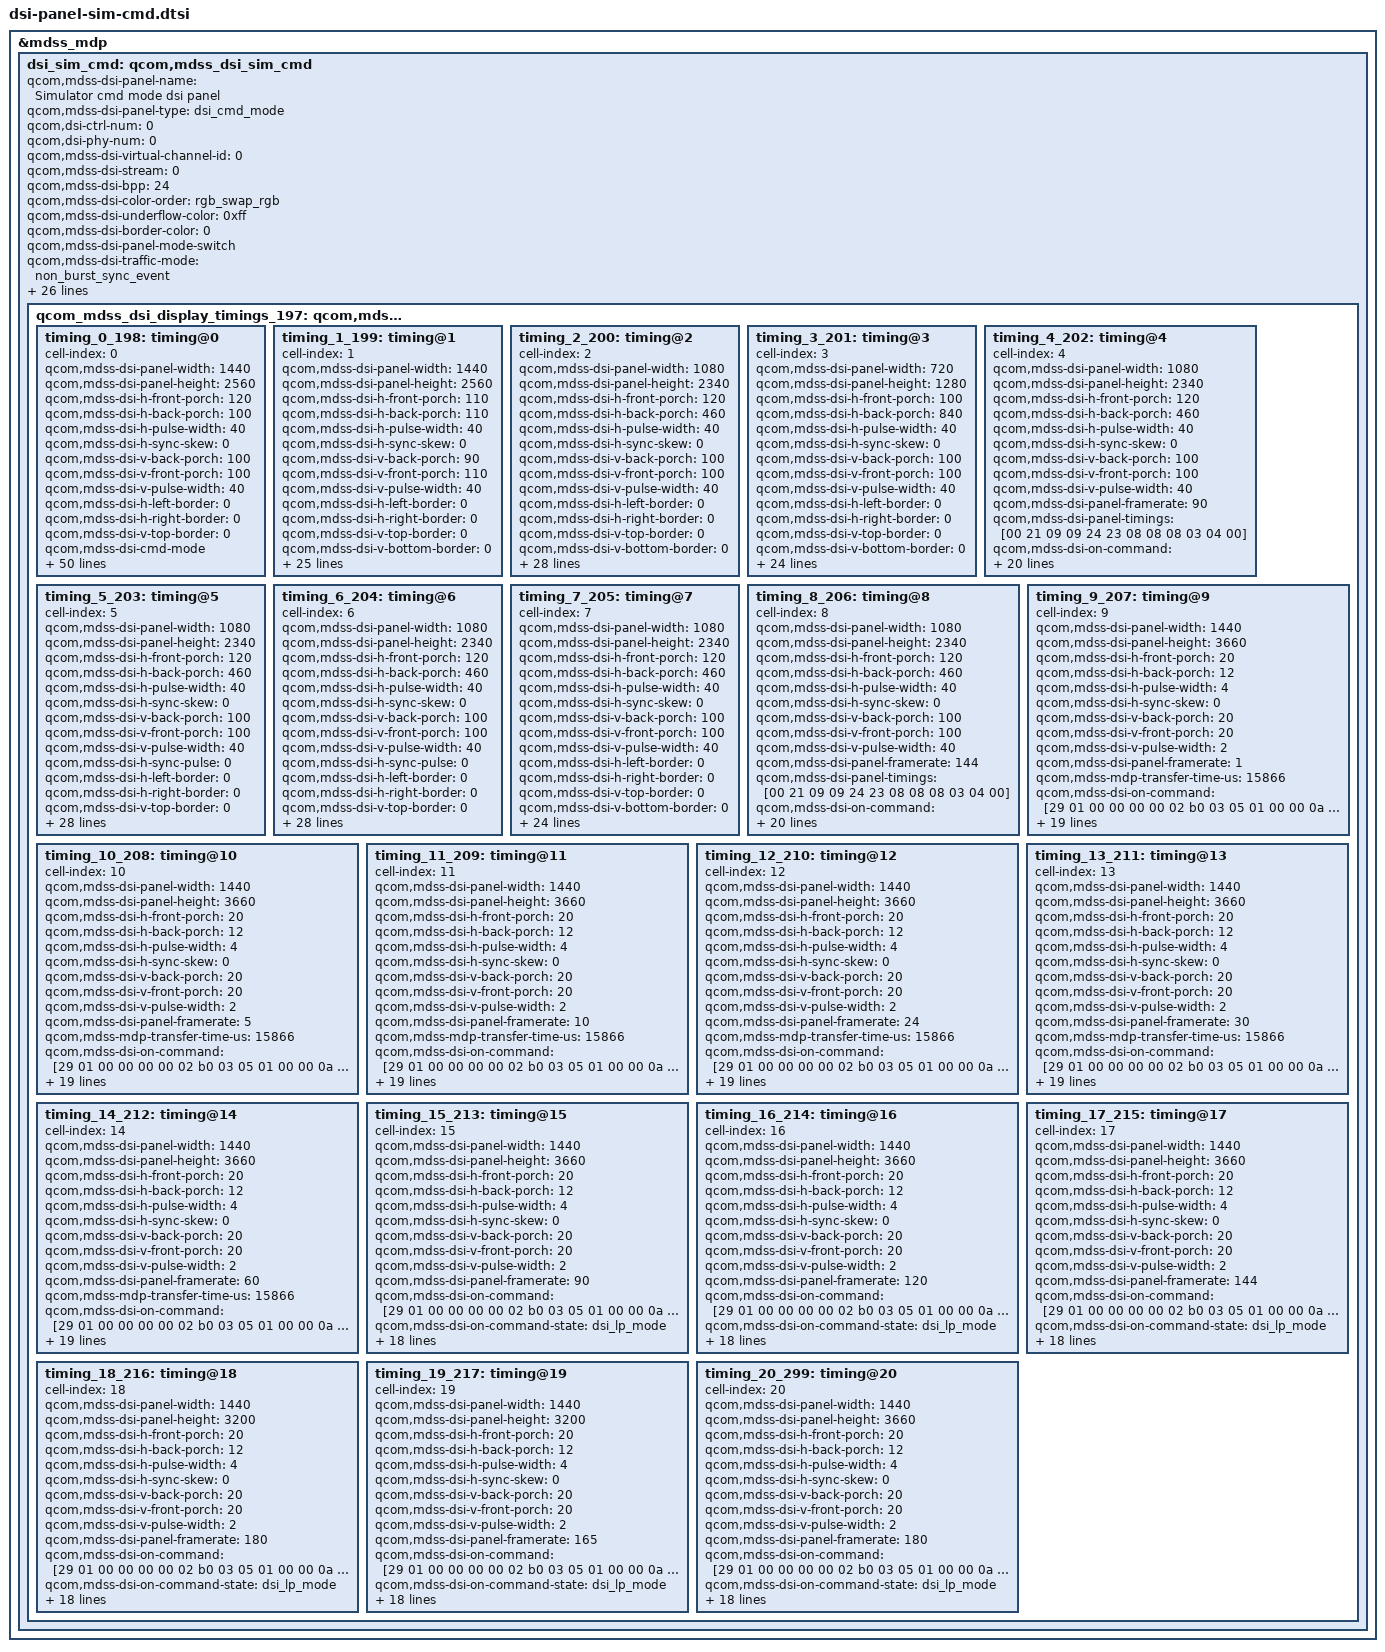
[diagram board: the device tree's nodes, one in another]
// SPDX-License-Identifier: BSD-3-Clause
/*
 * Copyright (c) Qualcomm Technologies, Inc. and/or its subsidiaries.
 */

&mdss_mdp {
	dsi_sim_cmd: qcom,mdss_dsi_sim_cmd {
		qcom,mdss-dsi-panel-name = "Simulator cmd mode dsi panel";
		qcom,mdss-dsi-panel-type = "dsi_cmd_mode";

		qcom,dsi-ctrl-num = <0>;
		qcom,dsi-phy-num = <0>;

		qcom,mdss-dsi-virtual-channel-id = <0>;
		qcom,mdss-dsi-stream = <0>;
		qcom,mdss-dsi-bpp = <24>;
		qcom,mdss-dsi-color-order = "rgb_swap_rgb";
		qcom,mdss-dsi-underflow-color = <0xff>;
		qcom,mdss-dsi-border-color = <0>;
		qcom,mdss-dsi-panel-mode-switch;
		qcom,mdss-dsi-traffic-mode = "non_burst_sync_event";
		qcom,mdss-dsi-bllp-eof-power-mode;
		qcom,mdss-dsi-bllp-power-mode;
		qcom,mdss-dsi-lane-0-state;
		qcom,mdss-dsi-lane-1-state;
		qcom,mdss-dsi-lane-2-state;
		qcom,mdss-dsi-lane-3-state;
		qcom,mdss-dsi-reset-sequence = <1 10>, <0 10>, <1 10>;
		qcom,mdss-dsi-t-clk-post = <0x03>;
		qcom,mdss-dsi-t-clk-pre = <0x27>;
		qcom,mdss-dsi-bl-max-level = <4095>;
		qcom,mdss-dsi-dma-trigger = "trigger_sw";
		qcom,mdss-dsi-mdp-trigger = "none";
		qcom,mdss-dsi-te-pin-select = <1>;
		qcom,mdss-dsi-wr-mem-start = <0x2c>;
		qcom,mdss-dsi-wr-mem-continue = <0x3c>;
		qcom,mdss-dsi-te-dcs-command = <1>;
		qcom,mdss-dsi-te-check-enable;
		qcom,mdss-dsi-te-using-wd;
		qcom,mdss-dsi-te-using-te-pin;
		qcom,mdss-dsi-panel-hdr-enabled;
		qcom,mdss-dsi-panel-hdr-color-primaries = <14500 15500 32000
			17000 15500 30000 8000 3000>;
		qcom,mdss-dsi-panel-peak-brightness = <4200000>;
		qcom,mdss-dsi-panel-blackness-level = <3230>;
		qcom,panel-ack-disabled;
		qcom,qsync-enable;

		qcom_mdss_dsi_display_timings_197: qcom,mdss-dsi-display-timings {
			timing_0_198: timing@0 {
				cell-index = <0>;
				qcom,mdss-dsi-panel-width = <1440>;
				qcom,mdss-dsi-panel-height = <2560>;
				qcom,mdss-dsi-h-front-porch = <120>;
				qcom,mdss-dsi-h-back-porch = <100>;
				qcom,mdss-dsi-h-pulse-width = <40>;
				qcom,mdss-dsi-h-sync-skew = <0>;
				qcom,mdss-dsi-v-back-porch = <100>;
				qcom,mdss-dsi-v-front-porch = <100>;
				qcom,mdss-dsi-v-pulse-width = <40>;
				qcom,mdss-dsi-h-left-border = <0>;
				qcom,mdss-dsi-h-right-border = <0>;
				qcom,mdss-dsi-v-top-border = <0>;
				qcom,mdss-dsi-cmd-mode;
				qcom,mdss-dsi-video-mode;
				qcom,mdss-dsi-v-bottom-border = <0>;
				qcom,mdss-dsi-panel-framerate = <60>;
				qcom,dsi-wd-jitter-enable;
				qcom,mdss-dsi-panel-jitter = <0x2 0x1>;
				qcom,dsi-wd-ltj-max-jitter = <0x4 0x1>;
				qcom,dsi-wd-ltj-time-sec = <3600>;
				qcom,mdss-dsi-panel-timings =
					[00 21 09 09 24 23 08 08 08 03 04 00];
				qcom,cmd-on-commands =
					[29 01 00 00 00 00 02 b0 03
					05 01 00 00 0a 00 01 00
					/* Soft reset, wait 10ms */
					15 01 00 00 0a 00 02 3a 77
					/* Set Pixel format (24 bpp) */
					39 01 00 00 0a 00 05 2a 00 00 04 ff
					/* Set Column address */
					39 01 00 00 0a 00 05 2b 00 00 05 9f
					/* Set page address */
					15 01 00 00 0a 00 02 35 00
					/* Set tear on */
					39 01 00 00 0a 00 03 44 00 00
					/* Set tear scan line */
					15 01 00 00 0a 00 02 51 ff
					/* write display brightness */
					15 01 00 00 0a 00 02 53 24
					/* write control brightness */
					15 01 00 00 0a 00 02 55 00
					/* CABC brightness */
					05 01 00 00 78 00 01 11
					/* exit sleep mode, wait 120ms */
					05 01 00 00 10 00 01 29];
				qcom,vid-on-commands =
					[29 01 00 00 00 00 02 b0 03
					05 01 00 00 0a 00 01 00
					/* Soft reset, wait 10ms */
					15 01 00 00 0a 00 02 3a 77
					/* Set Pixel format (24 bpp) */
					39 01 00 00 0a 00 05 2a 00 00 04 ff
					/* Set Column address */
					39 01 00 00 0a 00 05 2b 00 00 05 9f
					/* Set page address */
					15 01 00 00 0a 00 02 35 00
					/* Set tear on */
					39 01 00 00 0a 00 03 44 00 00
					/* Set tear scan line */
					15 01 00 00 0a 00 02 51 ff
					/* write display brightness */
					15 01 00 00 0a 00 02 53 24
					/* write control brightness */
					15 01 00 00 0a 00 02 55 00
					/* CABC brightness */
					05 01 00 00 f0 00 01 00];
				qcom,mdss-dsi-on-command = [
					15 01 00 00 00 00 02 FE 00
					29 01 00 00 00 00 05 2A 00 0A 01 CF
					29 01 00 00 00 00 05 2B 00 00 01 C5
					29 01 00 00 00 00 05 30 00 00 01 C5
					29 01 00 00 00 00 05 31 00 0A 01 CF
					15 01 00 00 00 00 02 35 00
					15 01 00 00 00 00 02 53 20
					15 01 00 00 00 00 02 51 FF
					15 01 00 00 00 00 02 63 FF
					05 01 00 00 00 00 02 12 00
					05 01 00 00 32 00 02 11 00
					05 01 00 00 00 00 02 29 00
				];
				qcom,mdss-dsi-on-command-state = "dsi_lp_mode";
				qcom,mdss-dsi-off-command =
					[05 01 00 00 32 00 02 28 00
					05 01 00 00 78 00 02 10 00];
				qcom,mdss-dsi-off-command-state = "dsi_hs_mode";
				qcom,video-mode-switch-out-commands = [
				  39 01 00 00 00 00 03 b0 a5 00
				  07 01 00 00 00 00 02 01 00
				  39 01 00 00 00 00 06 b2 00 5d 04 80 49
				];
				qcom,video-mode-switch-out-commands-state = "dsi_lp_mode";
				qcom,video-mode-switch-in-commands = [
				  39 01 00 00 00 00 03 b0 a5 00
				  07 01 00 00 00 00 02 01 00
				  39 01 00 00 00 00 06 b2 00 5d 04 80 49
				  15 01 00 00 00 00 02 3d 10
				  15 01 00 00 00 00 02 36 00
				  15 01 00 00 00 00 02 55 0c
				];
				qcom,video-mode-switch-in-commands-state = "dsi_lp_mode";
				qcom,cmd-mode-switch-in-commands = [
				  39 01 00 00 00 00 03 b0 a5 00
				  07 01 00 00 00 00 02 01 00
				  39 01 00 00 00 00 06 b2 00 5d 04 80 49
				  15 01 00 00 00 00 02 3d 11
				  15 01 00 00 00 00 02 36 00
				  15 01 00 00 00 00 02 55 0b
				];
				qcom,cmd-mode-switch-in-commands-state = "dsi_lp_mode";
				qcom,cmd-mode-switch-out-commands = [
				  39 01 00 00 00 00 03 b0 a5 00
				  07 01 00 00 00 00 02 01 00
				  39 01 00 00 00 00 06 b2 00 5d 01 02 49
				];
				qcom,cmd-mode-switch-out-commands-state = "dsi_lp_mode";
				qcom,mdss-dsi-qsync-on-commands =
					[15 01 00 00 00 00 02 51 00];
				qcom,mdss-dsi-qsync-on-commands-state =
					"dsi_hs_mode";
				qcom,mdss-dsi-qsync-off-commands =
					[15 01 00 00 00 00 02 51 00];
				qcom,mdss-dsi-qsync-off-commands-state =
					"dsi_hs_mode";

				qcom,compression-mode = "dsc";
				qcom,mdss-dsc-slice-height = <40>;
				qcom,mdss-dsc-slice-width = <720>;
				qcom,mdss-dsc-slice-per-pkt = <1>;
				qcom,mdss-dsc-bit-per-component = <8>;
				qcom,mdss-dsc-bit-per-pixel = <8>;
				qcom,mdss-dsc-block-prediction-enable;
			};

			timing_1_199: timing@1 {
				cell-index = <1>;
				qcom,mdss-dsi-panel-width = <1440>;
				qcom,mdss-dsi-panel-height = <2560>;
				qcom,mdss-dsi-h-front-porch = <110>;
				qcom,mdss-dsi-h-back-porch = <110>;
				qcom,mdss-dsi-h-pulse-width = <40>;
				qcom,mdss-dsi-h-sync-skew = <0>;
				qcom,mdss-dsi-v-back-porch = <90>;
				qcom,mdss-dsi-v-front-porch = <110>;
				qcom,mdss-dsi-v-pulse-width = <40>;
				qcom,mdss-dsi-h-left-border = <0>;
				qcom,mdss-dsi-h-right-border = <0>;
				qcom,mdss-dsi-v-top-border = <0>;
				qcom,mdss-dsi-v-bottom-border = <0>;
				qcom,mdss-dsi-panel-framerate = <60>;
				qcom,mdss-dsi-video-mode;
				qcom,mdss-dsi-panel-timings =
					[00 21 09 09 24 23 08 08 08 03 04 00];
				qcom,mdss-dsi-on-command =
					[29 01 00 00 00 00 02 b0 03
					05 01 00 00 0a 00 01 00
					/* Soft reset, wait 10ms */
					15 01 00 00 0a 00 02 3a 77
					/* Set Pixel format (24 bpp) */
					39 01 00 00 0a 00 05 2a 00 00 04 ff
					/* Set Column address */
					39 01 00 00 0a 00 05 2b 00 00 05 9f
					/* Set page address */
					15 01 00 00 0a 00 02 35 00
					/* Set tear on */
					39 01 00 00 0a 00 03 44 00 00
					/* Set tear scan line */
					15 01 00 00 0a 00 02 51 ff
					/* write display brightness */
					15 01 00 00 0a 00 02 53 24
					/* write control brightness */
					15 01 00 00 0a 00 02 55 00
					/* CABC brightness */
					05 01 00 00 f0 00 01 00];
				qcom,mdss-dsi-on-command-state = "dsi_lp_mode";
				qcom,mdss-dsi-off-command =
					[05 01 00 00 32 00 02 28 00
					05 01 00 00 78 00 02 10 00];
				qcom,mdss-dsi-off-command-state = "dsi_hs_mode";
				qcom,mdss-dsi-qsync-on-commands =
					[15 01 00 00 00 00 02 51 00];
				qcom,mdss-dsi-qsync-on-commands-state =
					"dsi_hs_mode";
				qcom,mdss-dsi-qsync-off-commands =
					[15 01 00 00 00 00 02 51 00];
				qcom,mdss-dsi-qsync-off-commands-state =
					"dsi_hs_mode";

				qcom,compression-mode = "dsc";
				qcom,mdss-dsc-slice-height = <40>;
				qcom,mdss-dsc-slice-width = <720>;
				qcom,mdss-dsc-slice-per-pkt = <1>;
				qcom,mdss-dsc-bit-per-component = <8>;
				qcom,mdss-dsc-bit-per-pixel = <8>;
				qcom,mdss-dsc-block-prediction-enable;
			};

			timing_2_200: timing@2 {
				cell-index = <2>;
				qcom,mdss-dsi-panel-width = <1080>;
				qcom,mdss-dsi-panel-height = <2340>;
				qcom,mdss-dsi-h-front-porch = <120>;
				qcom,mdss-dsi-h-back-porch = <460>;
				qcom,mdss-dsi-h-pulse-width = <40>;
				qcom,mdss-dsi-h-sync-skew = <0>;
				qcom,mdss-dsi-v-back-porch = <100>;
				qcom,mdss-dsi-v-front-porch = <100>;
				qcom,mdss-dsi-v-pulse-width = <40>;
				qcom,mdss-dsi-h-left-border = <0>;
				qcom,mdss-dsi-h-right-border = <0>;
				qcom,mdss-dsi-v-top-border = <0>;
				qcom,mdss-dsi-v-bottom-border = <0>;
				qcom,mdss-dsi-panel-framerate = <60>;
				qcom,dsi-wd-jitter-enable;
				qcom,mdss-dsi-panel-jitter = <0x2 0x1>;
				qcom,dsi-wd-ltj-max-jitter = <0x4 0x1>;
				qcom,dsi-wd-ltj-time-sec = <3600>;
				qcom,mdss-dsi-panel-timings =
					[00 21 09 09 24 23 08 08 08 03 04 00];
				qcom,mdss-dsi-on-command =
					[29 01 00 00 00 00 02 b0 03
					05 01 00 00 0a 00 01 00
					/* Soft reset, wait 10ms */
					15 01 00 00 0a 00 02 3a 77
					/* Set Pixel format (24 bpp) */
					39 01 00 00 0a 00 05 2a 00 00 04 ff
					/* Set Column address */
					39 01 00 00 0a 00 05 2b 00 00 05 9f
					/* Set page address */
					15 01 00 00 0a 00 02 35 00
					/* Set tear on */
					39 01 00 00 0a 00 03 44 00 00
					/* Set tear scan line */
					15 01 00 00 0a 00 02 51 ff
					/* write display brightness */
					15 01 00 00 0a 00 02 53 24
					 /* write control brightness */
					15 01 00 00 0a 00 02 55 00
					/* CABC brightness */
					05 01 00 00 f0 00 01 00];
				qcom,mdss-dsi-on-command-state = "dsi_lp_mode";
				qcom,mdss-dsi-off-command =
					[05 01 00 00 32 00 02 28 00
					05 01 00 00 78 00 02 10 00];
				qcom,mdss-dsi-off-command-state = "dsi_hs_mode";
				qcom,mdss-dsi-qsync-on-commands =
					[15 01 00 00 00 00 02 51 00];
				qcom,mdss-dsi-qsync-on-commands-state =
					"dsi_hs_mode";
				qcom,mdss-dsi-qsync-off-commands =
					[15 01 00 00 00 00 02 51 00];
				qcom,mdss-dsi-qsync-off-commands-state =
					"dsi_hs_mode";

				qcom,compression-mode = "dsc";
				qcom,mdss-dsc-slice-height = <20>;
				qcom,mdss-dsc-slice-width = <540>;
				qcom,mdss-dsc-slice-per-pkt = <1>;
				qcom,mdss-dsc-bit-per-component = <8>;
				qcom,mdss-dsc-bit-per-pixel = <8>;
				qcom,mdss-dsc-block-prediction-enable;
			};

			timing_3_201: timing@3 {
				cell-index = <3>;
				qcom,mdss-dsi-panel-width = <720>;
				qcom,mdss-dsi-panel-height = <1280>;
				qcom,mdss-dsi-h-front-porch = <100>;
				qcom,mdss-dsi-h-back-porch = <840>;
				qcom,mdss-dsi-h-pulse-width = <40>;
				qcom,mdss-dsi-h-sync-skew = <0>;
				qcom,mdss-dsi-v-back-porch = <100>;
				qcom,mdss-dsi-v-front-porch = <100>;
				qcom,mdss-dsi-v-pulse-width = <40>;
				qcom,mdss-dsi-h-left-border = <0>;
				qcom,mdss-dsi-h-right-border = <0>;
				qcom,mdss-dsi-v-top-border = <0>;
				qcom,mdss-dsi-v-bottom-border = <0>;
				qcom,mdss-dsi-panel-framerate = <60>;
				qcom,mdss-dsi-panel-timings =
					[00 21 09 09 24 23 08 08 08 03 04 00];
				qcom,mdss-dsi-on-command =
					[29 01 00 00 00 00 02 b0 03
					05 01 00 00 0a 00 01 00
					/* Soft reset, wait 10ms */
					15 01 00 00 0a 00 02 3a 77
					/* Set Pixel format (24 bpp) */
					39 01 00 00 0a 00 05 2a 00 00 04 ff
					/* Set Column address */
					39 01 00 00 0a 00 05 2b 00 00 05 9f
					/* Set page address */
					15 01 00 00 0a 00 02 35 00
					/* Set tear on */
					39 01 00 00 0a 00 03 44 00 00
					/* Set tear scan line */
					15 01 00 00 0a 00 02 51 ff
					/* write display brightness */
					15 01 00 00 0a 00 02 53 24
					 /* write control brightness */
					15 01 00 00 0a 00 02 55 00
					/* CABC brightness */
					05 01 00 00 f0 00 01 00];
				qcom,mdss-dsi-on-command-state = "dsi_lp_mode";
				qcom,mdss-dsi-off-command =
					[05 01 00 00 32 00 02 28 00
					05 01 00 00 78 00 02 10 00];
				qcom,mdss-dsi-off-command-state = "dsi_hs_mode";
				qcom,mdss-dsi-qsync-on-commands =
					[15 01 00 00 00 00 02 51 00];
				qcom,mdss-dsi-qsync-on-commands-state =
					"dsi_hs_mode";
				qcom,mdss-dsi-qsync-off-commands =
					[15 01 00 00 00 00 02 51 00];
				qcom,mdss-dsi-qsync-off-commands-state =
					"dsi_hs_mode";

				qcom,compression-mode = "dsc";
				qcom,mdss-dsc-slice-height = <40>;
				qcom,mdss-dsc-slice-width = <360>;
				qcom,mdss-dsc-slice-per-pkt = <1>;
				qcom,mdss-dsc-bit-per-component = <8>;
				qcom,mdss-dsc-bit-per-pixel = <8>;
				qcom,mdss-dsc-block-prediction-enable;
			};

			timing_4_202: timing@4 {
				cell-index = <4>;
				qcom,mdss-dsi-panel-width = <1080>;
				qcom,mdss-dsi-panel-height = <2340>;
				qcom,mdss-dsi-h-front-porch = <120>;
				qcom,mdss-dsi-h-back-porch = <460>;
				qcom,mdss-dsi-h-pulse-width = <40>;
				qcom,mdss-dsi-h-sync-skew = <0>;
				qcom,mdss-dsi-v-back-porch = <100>;
				qcom,mdss-dsi-v-front-porch = <100>;
				qcom,mdss-dsi-v-pulse-width = <40>;
				qcom,mdss-dsi-panel-framerate = <90>;
				qcom,mdss-dsi-panel-timings =
					[00 21 09 09 24 23 08 08 08 03 04 00];
				qcom,mdss-dsi-on-command =
					[29 01 00 00 00 00 02 b0 03
					05 01 00 00 0a 00 01 00
					/* Soft reset, wait 10ms */
					15 01 00 00 0a 00 02 3a 77
					/* Set Pixel format (24 bpp) */
					39 01 00 00 0a 00 05 2a 00 00 04 ff
					/* Set Column address */
					39 01 00 00 0a 00 05 2b 00 00 05 9f
					/* Set page address */
					15 01 00 00 0a 00 02 35 00
					/* Set tear on */
					39 01 00 00 0a 00 03 44 00 00
					/* Set tear scan line */
					15 01 00 00 0a 00 02 51 ff
					/* write display brightness */
					15 01 00 00 0a 00 02 53 24
					 /* write control brightness */
					15 01 00 00 0a 00 02 55 00
					/* CABC brightness */
					05 01 00 00 78 00 01 11
					/* exit sleep mode, wait 120ms */
					05 01 00 00 10 00 01 29];
					/* Set display on, wait 16ms */
				qcom,mdss-dsi-on-command-state = "dsi_lp_mode";
				qcom,mdss-dsi-off-command =
					[05 01 00 00 32 00 02 28 00
					05 01 00 00 78 00 02 10 00];
				qcom,mdss-dsi-off-command-state = "dsi_hs_mode";
				qcom,mdss-dsi-qsync-on-commands =
					[15 01 00 00 00 00 02 51 00];
				qcom,mdss-dsi-qsync-on-commands-state =
					"dsi_hs_mode";
				qcom,mdss-dsi-qsync-off-commands =
					[15 01 00 00 00 00 02 51 00];
				qcom,mdss-dsi-qsync-off-commands-state =
					"dsi_hs_mode";

				qcom,compression-mode = "dsc";
				qcom,mdss-dsc-slice-height = <20>;
				qcom,mdss-dsc-slice-width = <540>;
				qcom,mdss-dsc-slice-per-pkt = <1>;
				qcom,mdss-dsc-bit-per-component = <8>;
				qcom,mdss-dsc-bit-per-pixel = <8>;
				qcom,mdss-dsc-block-prediction-enable;
			};

			timing_5_203: timing@5 {
				cell-index = <5>;
				qcom,mdss-dsi-panel-width = <1080>;
				qcom,mdss-dsi-panel-height = <2340>;
				qcom,mdss-dsi-h-front-porch = <120>;
				qcom,mdss-dsi-h-back-porch = <460>;
				qcom,mdss-dsi-h-pulse-width = <40>;
				qcom,mdss-dsi-h-sync-skew = <0>;
				qcom,mdss-dsi-v-back-porch = <100>;
				qcom,mdss-dsi-v-front-porch = <100>;
				qcom,mdss-dsi-v-pulse-width = <40>;
				qcom,mdss-dsi-h-sync-pulse = <0>;
				qcom,mdss-dsi-h-left-border = <0>;
				qcom,mdss-dsi-h-right-border = <0>;
				qcom,mdss-dsi-v-top-border = <0>;
				qcom,mdss-dsi-v-bottom-border = <0>;
				qcom,mdss-dsi-panel-framerate = <180>;
				qcom,dsi-wd-jitter-enable;
				qcom,mdss-dsi-panel-jitter = <0x2 0x1>;
				qcom,dsi-wd-ltj-max-jitter = <0x4 0x1>;
				qcom,dsi-wd-ltj-time-sec = <3600>;
				qcom,disable-rsc-solver;

				qcom,mdss-dsi-on-command =
					[29 01 00 00 00 00 02 b0 03
					05 01 00 00 0a 00 01 00
					/* Soft reset, wait 10ms */
					15 01 00 00 0a 00 02 3a 77
					/* Set Pixel format (24 bpp) */
					39 01 00 00 0a 00 05 2a 00 00 04 ff
					/* Set Column address */
					39 01 00 00 0a 00 05 2b 00 00 05 9f
					/* Set page address */
					15 01 00 00 0a 00 02 35 00
					/* Set tear on */
					39 01 00 00 0a 00 03 44 00 00
					/* Set tear scan line */
					15 01 00 00 0a 00 02 51 ff
					/* write display brightness */
					15 01 00 00 0a 00 02 53 24
					 /* write control brightness */
					15 01 00 00 0a 00 02 55 00];
					/* CABC brightness */

				qcom,mdss-dsi-on-command-state = "dsi_lp_mode";
				qcom,mdss-dsi-off-command =
					[05 01 00 00 32 00 02 28 00
					05 01 00 00 78 00 02 10 00];
				qcom,mdss-dsi-off-command-state = "dsi_hs_mode";
				qcom,mdss-dsi-qsync-on-commands =
					[15 01 00 00 00 00 02 51 00];
				qcom,mdss-dsi-qsync-on-commands-state =
					"dsi_hs_mode";
				qcom,mdss-dsi-qsync-off-commands =
					[15 01 00 00 00 00 02 51 00];
				qcom,mdss-dsi-qsync-off-commands-state =
					"dsi_hs_mode";

				qcom,compression-mode = "dsc";
				qcom,mdss-dsc-slice-height = <20>;
				qcom,mdss-dsc-slice-width = <540>;
				qcom,mdss-dsc-slice-per-pkt = <1>;
				qcom,mdss-dsc-bit-per-component = <8>;
				qcom,mdss-dsc-bit-per-pixel = <8>;
				qcom,mdss-dsc-block-prediction-enable;
			};

			timing_6_204: timing@6 {
				cell-index = <6>;
				qcom,mdss-dsi-panel-width = <1080>;
				qcom,mdss-dsi-panel-height = <2340>;
				qcom,mdss-dsi-h-front-porch = <120>;
				qcom,mdss-dsi-h-back-porch = <460>;
				qcom,mdss-dsi-h-pulse-width = <40>;
				qcom,mdss-dsi-h-sync-skew = <0>;
				qcom,mdss-dsi-v-back-porch = <100>;
				qcom,mdss-dsi-v-front-porch = <100>;
				qcom,mdss-dsi-v-pulse-width = <40>;
				qcom,mdss-dsi-h-sync-pulse = <0>;
				qcom,mdss-dsi-h-left-border = <0>;
				qcom,mdss-dsi-h-right-border = <0>;
				qcom,mdss-dsi-v-top-border = <0>;
				qcom,mdss-dsi-v-bottom-border = <0>;
				qcom,mdss-dsi-panel-framerate = <240>;
				qcom,dsi-wd-jitter-enable;
				qcom,mdss-dsi-panel-jitter = <0x2 0x1>;
				qcom,dsi-wd-ltj-max-jitter = <0x4 0x1>;
				qcom,dsi-wd-ltj-time-sec = <3600>;
				qcom,disable-rsc-solver;

				qcom,mdss-dsi-on-command =
					[29 01 00 00 00 00 02 b0 03
					05 01 00 00 0a 00 01 00
					/* Soft reset, wait 10ms */
					15 01 00 00 0a 00 02 3a 77
					/* Set Pixel format (24 bpp) */
					39 01 00 00 0a 00 05 2a 00 00 04 ff
					/* Set Column address */
					39 01 00 00 0a 00 05 2b 00 00 05 9f
					/* Set page address */
					15 01 00 00 0a 00 02 35 00
					/* Set tear on */
					39 01 00 00 0a 00 03 44 00 00
					/* Set tear scan line */
					15 01 00 00 0a 00 02 51 ff
					/* write display brightness */
					15 01 00 00 0a 00 02 53 24
					 /* write control brightness */
					15 01 00 00 0a 00 02 55 00
					/* CABC brightness */
					05 01 00 00 f0 00 01 00];
				qcom,mdss-dsi-on-command-state = "dsi_lp_mode";
				qcom,mdss-dsi-off-command =
					[05 01 00 00 32 00 02 28 00
					05 01 00 00 78 00 02 10 00];
				qcom,mdss-dsi-off-command-state = "dsi_hs_mode";
				qcom,mdss-dsi-qsync-on-commands =
					[15 01 00 00 00 00 02 51 00];
				qcom,mdss-dsi-qsync-on-commands-state =
					"dsi_hs_mode";
				qcom,mdss-dsi-qsync-off-commands =
					[15 01 00 00 00 00 02 51 00];
				qcom,mdss-dsi-qsync-off-commands-state =
					"dsi_hs_mode";

				qcom,compression-mode = "dsc";
				qcom,mdss-dsc-slice-height = <20>;
				qcom,mdss-dsc-slice-width = <540>;
				qcom,mdss-dsc-slice-per-pkt = <1>;
				qcom,mdss-dsc-bit-per-component = <8>;
				qcom,mdss-dsc-bit-per-pixel = <8>;
				qcom,mdss-dsc-block-prediction-enable;
			};

			timing_7_205: timing@7 {
				cell-index = <7>;
				qcom,mdss-dsi-panel-width = <1080>;
				qcom,mdss-dsi-panel-height = <2340>;
				qcom,mdss-dsi-h-front-porch = <120>;
				qcom,mdss-dsi-h-back-porch = <460>;
				qcom,mdss-dsi-h-pulse-width = <40>;
				qcom,mdss-dsi-h-sync-skew = <0>;
				qcom,mdss-dsi-v-back-porch = <100>;
				qcom,mdss-dsi-v-front-porch = <100>;
				qcom,mdss-dsi-v-pulse-width = <40>;
				qcom,mdss-dsi-h-left-border = <0>;
				qcom,mdss-dsi-h-right-border = <0>;
				qcom,mdss-dsi-v-top-border = <0>;
				qcom,mdss-dsi-v-bottom-border = <0>;
				qcom,mdss-dsi-panel-framerate = <120>;
				qcom,mdss-dsi-panel-timings =
					[00 21 09 09 24 23 08 08 08 03 04 00];
				qcom,mdss-dsi-on-command =
					[29 01 00 00 00 00 02 b0 03
					05 01 00 00 0a 00 01 00
					/* Soft reset, wait 10ms */
					15 01 00 00 0a 00 02 3a 77
					/* Set Pixel format (24 bpp) */
					39 01 00 00 0a 00 05 2a 00 00 04 ff
					/* Set Column address */
					39 01 00 00 0a 00 05 2b 00 00 05 9f
					/* Set page address */
					15 01 00 00 0a 00 02 35 00
					/* Set tear on */
					39 01 00 00 0a 00 03 44 00 00
					/* Set tear scan line */
					15 01 00 00 0a 00 02 51 ff
					/* write display brightness */
					15 01 00 00 0a 00 02 53 24
					 /* write control brightness */
					15 01 00 00 0a 00 02 55 00
					/* CABC brightness */
					05 01 00 00 78 00 01 11
					/* exit sleep mode, wait 120ms */
					05 01 00 00 10 00 01 29];
					/* Set display on, wait 16ms */
				qcom,mdss-dsi-on-command-state = "dsi_lp_mode";
				qcom,mdss-dsi-off-command =
					[05 01 00 00 32 00 02 28 00
					05 01 00 00 78 00 02 10 00];
				qcom,mdss-dsi-off-command-state = "dsi_hs_mode";
				qcom,mdss-dsi-qsync-on-commands =
					[15 01 00 00 00 00 02 51 00];
				qcom,mdss-dsi-qsync-on-commands-state =
					"dsi_hs_mode";
				qcom,mdss-dsi-qsync-off-commands =
					[15 01 00 00 00 00 02 51 00];
				qcom,mdss-dsi-qsync-off-commands-state =
					"dsi_hs_mode";

				qcom,compression-mode = "dsc";
				qcom,mdss-dsc-slice-height = <20>;
				qcom,mdss-dsc-slice-width = <540>;
				qcom,mdss-dsc-slice-per-pkt = <1>;
				qcom,mdss-dsc-bit-per-component = <8>;
				qcom,mdss-dsc-bit-per-pixel = <8>;
				qcom,mdss-dsc-block-prediction-enable;
			};

			timing_8_206: timing@8 {
				cell-index = <8>;
				qcom,mdss-dsi-panel-width = <1080>;
				qcom,mdss-dsi-panel-height = <2340>;
				qcom,mdss-dsi-h-front-porch = <120>;
				qcom,mdss-dsi-h-back-porch = <460>;
				qcom,mdss-dsi-h-pulse-width = <40>;
				qcom,mdss-dsi-h-sync-skew = <0>;
				qcom,mdss-dsi-v-back-porch = <100>;
				qcom,mdss-dsi-v-front-porch = <100>;
				qcom,mdss-dsi-v-pulse-width = <40>;
				qcom,mdss-dsi-panel-framerate = <144>;
				qcom,mdss-dsi-panel-timings =
					[00 21 09 09 24 23 08 08 08 03 04 00];
				qcom,mdss-dsi-on-command =
					[29 01 00 00 00 00 02 b0 03
					05 01 00 00 0a 00 01 00
					/* Soft reset, wait 10ms */
					15 01 00 00 0a 00 02 3a 77
					/* Set Pixel format (24 bpp) */
					39 01 00 00 0a 00 05 2a 00 00 04 ff
					/* Set Column address */
					39 01 00 00 0a 00 05 2b 00 00 05 9f
					/* Set page address */
					15 01 00 00 0a 00 02 35 00
					/* Set tear on */
					39 01 00 00 0a 00 03 44 00 00
					/* Set tear scan line */
					15 01 00 00 0a 00 02 51 ff
					/* write display brightness */
					15 01 00 00 0a 00 02 53 24
					 /* write control brightness */
					15 01 00 00 0a 00 02 55 00
					/* CABC brightness */
					05 01 00 00 78 00 01 11
					/* exit sleep mode, wait 120ms */
					05 01 00 00 10 00 01 29];
					/* Set display on, wait 16ms */
				qcom,mdss-dsi-on-command-state = "dsi_lp_mode";
				qcom,mdss-dsi-off-command =
					[05 01 00 00 32 00 02 28 00
					05 01 00 00 78 00 02 10 00];
				qcom,mdss-dsi-off-command-state = "dsi_hs_mode";
				qcom,mdss-dsi-qsync-on-commands =
					[15 01 00 00 00 00 02 51 00];
				qcom,mdss-dsi-qsync-on-commands-state =
					"dsi_hs_mode";
				qcom,mdss-dsi-qsync-off-commands =
					[15 01 00 00 00 00 02 51 00];
				qcom,mdss-dsi-qsync-off-commands-state =
					"dsi_hs_mode";

				qcom,compression-mode = "dsc";
				qcom,mdss-dsc-slice-height = <20>;
				qcom,mdss-dsc-slice-width = <540>;
				qcom,mdss-dsc-slice-per-pkt = <1>;
				qcom,mdss-dsc-bit-per-component = <8>;
				qcom,mdss-dsc-bit-per-pixel = <8>;
				qcom,mdss-dsc-block-prediction-enable;
			};

			timing_9_207: timing@9 {
				cell-index = <9>;
				qcom,mdss-dsi-panel-width = <1440>;
				qcom,mdss-dsi-panel-height = <3660>;
				qcom,mdss-dsi-h-front-porch = <20>;
				qcom,mdss-dsi-h-back-porch = <12>;
				qcom,mdss-dsi-h-pulse-width = <4>;
				qcom,mdss-dsi-h-sync-skew = <0>;
				qcom,mdss-dsi-v-back-porch = <20>;
				qcom,mdss-dsi-v-front-porch = <20>;
				qcom,mdss-dsi-v-pulse-width = <2>;
				qcom,mdss-dsi-panel-framerate = <1>;
				qcom,mdss-mdp-transfer-time-us = <15866>;
				qcom,mdss-dsi-on-command =
					[29 01 00 00 00 00 02 b0 03
					05 01 00 00 0a 00 01 00
					/* Soft reset, wait 10ms */
					15 01 00 00 0a 00 02 3a 77
					/* Set Pixel format (24 bpp) */
					39 01 00 00 0a 00 05 2a 00 00 04 ff
					/* Set Column address */
					39 01 00 00 0a 00 05 2b 00 00 05 9f
					/* Set page address */
					15 01 00 00 0a 00 02 35 00
					/* Set tear on */
					39 01 00 00 0a 00 03 44 00 00
					/* Set tear scan line */
					15 01 00 00 0a 00 02 51 ff
					/* write display brightness */
					15 01 00 00 0a 00 02 53 24
					 /* write control brightness */
					15 01 00 00 0a 00 02 55 00
					/* CABC brightness */
					05 01 00 00 78 00 01 11
					/* exit sleep mode, wait 120ms */
					05 01 00 00 10 00 01 29];
					/* Set display on, wait 16ms */
				qcom,mdss-dsi-on-command-state = "dsi_lp_mode";
				qcom,mdss-dsi-off-command =
					[05 01 00 00 32 00 02 28 00
					05 01 00 00 78 00 02 10 00];
				qcom,mdss-dsi-off-command-state = "dsi_hs_mode";
				qcom,mdss-dsi-qsync-on-commands =
					[15 01 00 00 00 00 02 51 00];
				qcom,mdss-dsi-qsync-on-commands-state =
					"dsi_hs_mode";
				qcom,mdss-dsi-qsync-off-commands =
					[15 01 00 00 00 00 02 51 00];
				qcom,mdss-dsi-qsync-off-commands-state =
					"dsi_hs_mode";

				qcom,compression-mode = "dsc";
				qcom,mdss-dsc-slice-height = <20>;
				qcom,mdss-dsc-slice-width = <720>;
				qcom,mdss-dsc-slice-per-pkt = <1>;
				qcom,mdss-dsc-bit-per-component = <8>;
				qcom,mdss-dsc-bit-per-pixel = <8>;
				qcom,mdss-dsc-block-prediction-enable;
			};

			timing_10_208: timing@10 {
				cell-index = <10>;
				qcom,mdss-dsi-panel-width = <1440>;
				qcom,mdss-dsi-panel-height = <3660>;
				qcom,mdss-dsi-h-front-porch = <20>;
				qcom,mdss-dsi-h-back-porch = <12>;
				qcom,mdss-dsi-h-pulse-width = <4>;
				qcom,mdss-dsi-h-sync-skew = <0>;
				qcom,mdss-dsi-v-back-porch = <20>;
				qcom,mdss-dsi-v-front-porch = <20>;
				qcom,mdss-dsi-v-pulse-width = <2>;
				qcom,mdss-dsi-panel-framerate = <5>;
				qcom,mdss-mdp-transfer-time-us = <15866>;
				qcom,mdss-dsi-on-command =
					[29 01 00 00 00 00 02 b0 03
					05 01 00 00 0a 00 01 00
					/* Soft reset, wait 10ms */
					15 01 00 00 0a 00 02 3a 77
					/* Set Pixel format (24 bpp) */
					39 01 00 00 0a 00 05 2a 00 00 04 ff
					/* Set Column address */
					39 01 00 00 0a 00 05 2b 00 00 05 9f
					/* Set page address */
					15 01 00 00 0a 00 02 35 00
					/* Set tear on */
					39 01 00 00 0a 00 03 44 00 00
					/* Set tear scan line */
					15 01 00 00 0a 00 02 51 ff
					/* write display brightness */
					15 01 00 00 0a 00 02 53 24
					 /* write control brightness */
					15 01 00 00 0a 00 02 55 00
					/* CABC brightness */
					05 01 00 00 78 00 01 11
					/* exit sleep mode, wait 120ms */
					05 01 00 00 10 00 01 29];
					/* Set display on, wait 16ms */
				qcom,mdss-dsi-on-command-state = "dsi_lp_mode";
				qcom,mdss-dsi-off-command =
					[05 01 00 00 32 00 02 28 00
					05 01 00 00 78 00 02 10 00];
				qcom,mdss-dsi-off-command-state = "dsi_hs_mode";
				qcom,mdss-dsi-qsync-on-commands =
					[15 01 00 00 00 00 02 51 00];
				qcom,mdss-dsi-qsync-on-commands-state =
					"dsi_hs_mode";
				qcom,mdss-dsi-qsync-off-commands =
					[15 01 00 00 00 00 02 51 00];
				qcom,mdss-dsi-qsync-off-commands-state =
					"dsi_hs_mode";

				qcom,compression-mode = "dsc";
				qcom,mdss-dsc-slice-height = <20>;
				qcom,mdss-dsc-slice-width = <720>;
				qcom,mdss-dsc-slice-per-pkt = <1>;
				qcom,mdss-dsc-bit-per-component = <8>;
				qcom,mdss-dsc-bit-per-pixel = <8>;
				qcom,mdss-dsc-block-prediction-enable;
			};

			timing_11_209: timing@11 {
				cell-index = <11>;
				qcom,mdss-dsi-panel-width = <1440>;
				qcom,mdss-dsi-panel-height = <3660>;
				qcom,mdss-dsi-h-front-porch = <20>;
				qcom,mdss-dsi-h-back-porch = <12>;
				qcom,mdss-dsi-h-pulse-width = <4>;
				qcom,mdss-dsi-h-sync-skew = <0>;
				qcom,mdss-dsi-v-back-porch = <20>;
				qcom,mdss-dsi-v-front-porch = <20>;
				qcom,mdss-dsi-v-pulse-width = <2>;
				qcom,mdss-dsi-panel-framerate = <10>;
				qcom,mdss-mdp-transfer-time-us = <15866>;
				qcom,mdss-dsi-on-command =
					[29 01 00 00 00 00 02 b0 03
					05 01 00 00 0a 00 01 00
					/* Soft reset, wait 10ms */
					15 01 00 00 0a 00 02 3a 77
					/* Set Pixel format (24 bpp) */
					39 01 00 00 0a 00 05 2a 00 00 04 ff
					/* Set Column address */
					39 01 00 00 0a 00 05 2b 00 00 05 9f
					/* Set page address */
					15 01 00 00 0a 00 02 35 00
					/* Set tear on */
					39 01 00 00 0a 00 03 44 00 00
					/* Set tear scan line */
					15 01 00 00 0a 00 02 51 ff
					/* write display brightness */
					15 01 00 00 0a 00 02 53 24
					 /* write control brightness */
					15 01 00 00 0a 00 02 55 00
					/* CABC brightness */
					05 01 00 00 78 00 01 11
					/* exit sleep mode, wait 120ms */
					05 01 00 00 10 00 01 29];
					/* Set display on, wait 16ms */
				qcom,mdss-dsi-on-command-state = "dsi_lp_mode";
				qcom,mdss-dsi-off-command =
					[05 01 00 00 32 00 02 28 00
					05 01 00 00 78 00 02 10 00];
				qcom,mdss-dsi-off-command-state = "dsi_hs_mode";
				qcom,mdss-dsi-qsync-on-commands =
					[15 01 00 00 00 00 02 51 00];
				qcom,mdss-dsi-qsync-on-commands-state =
					"dsi_hs_mode";
				qcom,mdss-dsi-qsync-off-commands =
					[15 01 00 00 00 00 02 51 00];
				qcom,mdss-dsi-qsync-off-commands-state =
					"dsi_hs_mode";

				qcom,compression-mode = "dsc";
				qcom,mdss-dsc-slice-height = <20>;
				qcom,mdss-dsc-slice-width = <720>;
				qcom,mdss-dsc-slice-per-pkt = <1>;
				qcom,mdss-dsc-bit-per-component = <8>;
				qcom,mdss-dsc-bit-per-pixel = <8>;
				qcom,mdss-dsc-block-prediction-enable;
			};

			timing_12_210: timing@12 {
				cell-index = <12>;
				qcom,mdss-dsi-panel-width = <1440>;
				qcom,mdss-dsi-panel-height = <3660>;
				qcom,mdss-dsi-h-front-porch = <20>;
				qcom,mdss-dsi-h-back-porch = <12>;
				qcom,mdss-dsi-h-pulse-width = <4>;
				qcom,mdss-dsi-h-sync-skew = <0>;
				qcom,mdss-dsi-v-back-porch = <20>;
				qcom,mdss-dsi-v-front-porch = <20>;
				qcom,mdss-dsi-v-pulse-width = <2>;
				qcom,mdss-dsi-panel-framerate = <24>;
				qcom,mdss-mdp-transfer-time-us = <15866>;
				qcom,mdss-dsi-on-command =
					[29 01 00 00 00 00 02 b0 03
					05 01 00 00 0a 00 01 00
					/* Soft reset, wait 10ms */
					15 01 00 00 0a 00 02 3a 77
					/* Set Pixel format (24 bpp) */
					39 01 00 00 0a 00 05 2a 00 00 04 ff
					/* Set Column address */
					39 01 00 00 0a 00 05 2b 00 00 05 9f
					/* Set page address */
					15 01 00 00 0a 00 02 35 00
					/* Set tear on */
					39 01 00 00 0a 00 03 44 00 00
					/* Set tear scan line */
					15 01 00 00 0a 00 02 51 ff
					/* write display brightness */
					15 01 00 00 0a 00 02 53 24
					 /* write control brightness */
					15 01 00 00 0a 00 02 55 00
					/* CABC brightness */
					05 01 00 00 78 00 01 11
					/* exit sleep mode, wait 120ms */
					05 01 00 00 10 00 01 29];
					/* Set display on, wait 16ms */
				qcom,mdss-dsi-on-command-state = "dsi_lp_mode";
				qcom,mdss-dsi-off-command =
					[05 01 00 00 32 00 02 28 00
					05 01 00 00 78 00 02 10 00];
				qcom,mdss-dsi-off-command-state = "dsi_hs_mode";
				qcom,mdss-dsi-qsync-on-commands =
					[15 01 00 00 00 00 02 51 00];
				qcom,mdss-dsi-qsync-on-commands-state =
					"dsi_hs_mode";
				qcom,mdss-dsi-qsync-off-commands =
					[15 01 00 00 00 00 02 51 00];
				qcom,mdss-dsi-qsync-off-commands-state =
					"dsi_hs_mode";

				qcom,compression-mode = "dsc";
				qcom,mdss-dsc-slice-height = <20>;
				qcom,mdss-dsc-slice-width = <720>;
				qcom,mdss-dsc-slice-per-pkt = <1>;
				qcom,mdss-dsc-bit-per-component = <8>;
				qcom,mdss-dsc-bit-per-pixel = <8>;
				qcom,mdss-dsc-block-prediction-enable;
			};

			timing_13_211: timing@13 {
				cell-index = <13>;
				qcom,mdss-dsi-panel-width = <1440>;
				qcom,mdss-dsi-panel-height = <3660>;
				qcom,mdss-dsi-h-front-porch = <20>;
				qcom,mdss-dsi-h-back-porch = <12>;
				qcom,mdss-dsi-h-pulse-width = <4>;
				qcom,mdss-dsi-h-sync-skew = <0>;
				qcom,mdss-dsi-v-back-porch = <20>;
				qcom,mdss-dsi-v-front-porch = <20>;
				qcom,mdss-dsi-v-pulse-width = <2>;
				qcom,mdss-dsi-panel-framerate = <30>;
				qcom,mdss-mdp-transfer-time-us = <15866>;
				qcom,mdss-dsi-on-command =
					[29 01 00 00 00 00 02 b0 03
					05 01 00 00 0a 00 01 00
					/* Soft reset, wait 10ms */
					15 01 00 00 0a 00 02 3a 77
					/* Set Pixel format (24 bpp) */
					39 01 00 00 0a 00 05 2a 00 00 04 ff
					/* Set Column address */
					39 01 00 00 0a 00 05 2b 00 00 05 9f
					/* Set page address */
					15 01 00 00 0a 00 02 35 00
					/* Set tear on */
					39 01 00 00 0a 00 03 44 00 00
					/* Set tear scan line */
					15 01 00 00 0a 00 02 51 ff
					/* write display brightness */
					15 01 00 00 0a 00 02 53 24
					 /* write control brightness */
					15 01 00 00 0a 00 02 55 00
					/* CABC brightness */
					05 01 00 00 78 00 01 11
					/* exit sleep mode, wait 120ms */
					05 01 00 00 10 00 01 29];
					/* Set display on, wait 16ms */
				qcom,mdss-dsi-on-command-state = "dsi_lp_mode";
				qcom,mdss-dsi-off-command =
					[05 01 00 00 32 00 02 28 00
					05 01 00 00 78 00 02 10 00];
				qcom,mdss-dsi-off-command-state = "dsi_hs_mode";
				qcom,mdss-dsi-qsync-on-commands =
					[15 01 00 00 00 00 02 51 00];
				qcom,mdss-dsi-qsync-on-commands-state =
					"dsi_hs_mode";
				qcom,mdss-dsi-qsync-off-commands =
					[15 01 00 00 00 00 02 51 00];
				qcom,mdss-dsi-qsync-off-commands-state =
					"dsi_hs_mode";

				qcom,compression-mode = "dsc";
				qcom,mdss-dsc-slice-height = <20>;
				qcom,mdss-dsc-slice-width = <720>;
				qcom,mdss-dsc-slice-per-pkt = <1>;
				qcom,mdss-dsc-bit-per-component = <8>;
				qcom,mdss-dsc-bit-per-pixel = <8>;
				qcom,mdss-dsc-block-prediction-enable;
			};

			timing_14_212: timing@14 {
				cell-index = <14>;
				qcom,mdss-dsi-panel-width = <1440>;
				qcom,mdss-dsi-panel-height = <3660>;
				qcom,mdss-dsi-h-front-porch = <20>;
				qcom,mdss-dsi-h-back-porch = <12>;
				qcom,mdss-dsi-h-pulse-width = <4>;
				qcom,mdss-dsi-h-sync-skew = <0>;
				qcom,mdss-dsi-v-back-porch = <20>;
				qcom,mdss-dsi-v-front-porch = <20>;
				qcom,mdss-dsi-v-pulse-width = <2>;
				qcom,mdss-dsi-panel-framerate = <60>;
				qcom,mdss-mdp-transfer-time-us = <15866>;
				qcom,mdss-dsi-on-command =
					[29 01 00 00 00 00 02 b0 03
					05 01 00 00 0a 00 01 00
					/* Soft reset, wait 10ms */
					15 01 00 00 0a 00 02 3a 77
					/* Set Pixel format (24 bpp) */
					39 01 00 00 0a 00 05 2a 00 00 04 ff
					/* Set Column address */
					39 01 00 00 0a 00 05 2b 00 00 05 9f
					/* Set page address */
					15 01 00 00 0a 00 02 35 00
					/* Set tear on */
					39 01 00 00 0a 00 03 44 00 00
					/* Set tear scan line */
					15 01 00 00 0a 00 02 51 ff
					/* write display brightness */
					15 01 00 00 0a 00 02 53 24
					 /* write control brightness */
					15 01 00 00 0a 00 02 55 00
					/* CABC brightness */
					05 01 00 00 78 00 01 11
					/* exit sleep mode, wait 120ms */
					05 01 00 00 10 00 01 29];
					/* Set display on, wait 16ms */
				qcom,mdss-dsi-on-command-state = "dsi_lp_mode";
				qcom,mdss-dsi-off-command =
					[05 01 00 00 32 00 02 28 00
					05 01 00 00 78 00 02 10 00];
				qcom,mdss-dsi-off-command-state = "dsi_hs_mode";
				qcom,mdss-dsi-qsync-on-commands =
					[15 01 00 00 00 00 02 51 00];
				qcom,mdss-dsi-qsync-on-commands-state =
					"dsi_hs_mode";
				qcom,mdss-dsi-qsync-off-commands =
					[15 01 00 00 00 00 02 51 00];
				qcom,mdss-dsi-qsync-off-commands-state =
					"dsi_hs_mode";

				qcom,compression-mode = "dsc";
				qcom,mdss-dsc-slice-height = <20>;
				qcom,mdss-dsc-slice-width = <720>;
				qcom,mdss-dsc-slice-per-pkt = <1>;
				qcom,mdss-dsc-bit-per-component = <8>;
				qcom,mdss-dsc-bit-per-pixel = <8>;
				qcom,mdss-dsc-block-prediction-enable;
			};

			timing_15_213: timing@15 {
				cell-index = <15>;
				qcom,mdss-dsi-panel-width = <1440>;
				qcom,mdss-dsi-panel-height = <3660>;
				qcom,mdss-dsi-h-front-porch = <20>;
				qcom,mdss-dsi-h-back-porch = <12>;
				qcom,mdss-dsi-h-pulse-width = <4>;
				qcom,mdss-dsi-h-sync-skew = <0>;
				qcom,mdss-dsi-v-back-porch = <20>;
				qcom,mdss-dsi-v-front-porch = <20>;
				qcom,mdss-dsi-v-pulse-width = <2>;
				qcom,mdss-dsi-panel-framerate = <90>;
				qcom,mdss-dsi-on-command =
					[29 01 00 00 00 00 02 b0 03
					05 01 00 00 0a 00 01 00
					/* Soft reset, wait 10ms */
					15 01 00 00 0a 00 02 3a 77
					/* Set Pixel format (24 bpp) */
					39 01 00 00 0a 00 05 2a 00 00 04 ff
					/* Set Column address */
					39 01 00 00 0a 00 05 2b 00 00 05 9f
					/* Set page address */
					15 01 00 00 0a 00 02 35 00
					/* Set tear on */
					39 01 00 00 0a 00 03 44 00 00
					/* Set tear scan line */
					15 01 00 00 0a 00 02 51 ff
					/* write display brightness */
					15 01 00 00 0a 00 02 53 24
					 /* write control brightness */
					15 01 00 00 0a 00 02 55 00
					/* CABC brightness */
					05 01 00 00 78 00 01 11
					/* exit sleep mode, wait 120ms */
					05 01 00 00 10 00 01 29];
					/* Set display on, wait 16ms */
				qcom,mdss-dsi-on-command-state = "dsi_lp_mode";
				qcom,mdss-dsi-off-command =
					[05 01 00 00 32 00 02 28 00
					05 01 00 00 78 00 02 10 00];
				qcom,mdss-dsi-off-command-state = "dsi_hs_mode";
				qcom,mdss-dsi-qsync-on-commands =
					[15 01 00 00 00 00 02 51 00];
				qcom,mdss-dsi-qsync-on-commands-state =
					"dsi_hs_mode";
				qcom,mdss-dsi-qsync-off-commands =
					[15 01 00 00 00 00 02 51 00];
				qcom,mdss-dsi-qsync-off-commands-state =
					"dsi_hs_mode";

				qcom,compression-mode = "dsc";
				qcom,mdss-dsc-slice-height = <20>;
				qcom,mdss-dsc-slice-width = <720>;
				qcom,mdss-dsc-slice-per-pkt = <1>;
				qcom,mdss-dsc-bit-per-component = <8>;
				qcom,mdss-dsc-bit-per-pixel = <8>;
				qcom,mdss-dsc-block-prediction-enable;
			};

			timing_16_214: timing@16 {
				cell-index = <16>;
				qcom,mdss-dsi-panel-width = <1440>;
				qcom,mdss-dsi-panel-height = <3660>;
				qcom,mdss-dsi-h-front-porch = <20>;
				qcom,mdss-dsi-h-back-porch = <12>;
				qcom,mdss-dsi-h-pulse-width = <4>;
				qcom,mdss-dsi-h-sync-skew = <0>;
				qcom,mdss-dsi-v-back-porch = <20>;
				qcom,mdss-dsi-v-front-porch = <20>;
				qcom,mdss-dsi-v-pulse-width = <2>;
				qcom,mdss-dsi-panel-framerate = <120>;
				qcom,mdss-dsi-on-command =
					[29 01 00 00 00 00 02 b0 03
					05 01 00 00 0a 00 01 00
					/* Soft reset, wait 10ms */
					15 01 00 00 0a 00 02 3a 77
					/* Set Pixel format (24 bpp) */
					39 01 00 00 0a 00 05 2a 00 00 04 ff
					/* Set Column address */
					39 01 00 00 0a 00 05 2b 00 00 05 9f
					/* Set page address */
					15 01 00 00 0a 00 02 35 00
					/* Set tear on */
					39 01 00 00 0a 00 03 44 00 00
					/* Set tear scan line */
					15 01 00 00 0a 00 02 51 ff
					/* write display brightness */
					15 01 00 00 0a 00 02 53 24
					 /* write control brightness */
					15 01 00 00 0a 00 02 55 00
					/* CABC brightness */
					05 01 00 00 78 00 01 11
					/* exit sleep mode, wait 120ms */
					05 01 00 00 10 00 01 29];
					/* Set display on, wait 16ms */
				qcom,mdss-dsi-on-command-state = "dsi_lp_mode";
				qcom,mdss-dsi-off-command =
					[05 01 00 00 32 00 02 28 00
					05 01 00 00 78 00 02 10 00];
				qcom,mdss-dsi-off-command-state = "dsi_hs_mode";
				qcom,mdss-dsi-qsync-on-commands =
					[15 01 00 00 00 00 02 51 00];
				qcom,mdss-dsi-qsync-on-commands-state =
					"dsi_hs_mode";
				qcom,mdss-dsi-qsync-off-commands =
					[15 01 00 00 00 00 02 51 00];
				qcom,mdss-dsi-qsync-off-commands-state =
					"dsi_hs_mode";

				qcom,compression-mode = "dsc";
				qcom,mdss-dsc-slice-height = <20>;
				qcom,mdss-dsc-slice-width = <720>;
				qcom,mdss-dsc-slice-per-pkt = <1>;
				qcom,mdss-dsc-bit-per-component = <8>;
				qcom,mdss-dsc-bit-per-pixel = <8>;
				qcom,mdss-dsc-block-prediction-enable;
			};

			timing_17_215: timing@17 {
				cell-index = <17>;
				qcom,mdss-dsi-panel-width = <1440>;
				qcom,mdss-dsi-panel-height = <3660>;
				qcom,mdss-dsi-h-front-porch = <20>;
				qcom,mdss-dsi-h-back-porch = <12>;
				qcom,mdss-dsi-h-pulse-width = <4>;
				qcom,mdss-dsi-h-sync-skew = <0>;
				qcom,mdss-dsi-v-back-porch = <20>;
				qcom,mdss-dsi-v-front-porch = <20>;
				qcom,mdss-dsi-v-pulse-width = <2>;
				qcom,mdss-dsi-panel-framerate = <144>;
				qcom,mdss-dsi-on-command =
					[29 01 00 00 00 00 02 b0 03
					05 01 00 00 0a 00 01 00
					/* Soft reset, wait 10ms */
					15 01 00 00 0a 00 02 3a 77
					/* Set Pixel format (24 bpp) */
					39 01 00 00 0a 00 05 2a 00 00 04 ff
					/* Set Column address */
					39 01 00 00 0a 00 05 2b 00 00 05 9f
					/* Set page address */
					15 01 00 00 0a 00 02 35 00
					/* Set tear on */
					39 01 00 00 0a 00 03 44 00 00
					/* Set tear scan line */
					15 01 00 00 0a 00 02 51 ff
					/* write display brightness */
					15 01 00 00 0a 00 02 53 24
					 /* write control brightness */
					15 01 00 00 0a 00 02 55 00
					/* CABC brightness */
					05 01 00 00 78 00 01 11
					/* exit sleep mode, wait 120ms */
					05 01 00 00 10 00 01 29];
					/* Set display on, wait 16ms */
				qcom,mdss-dsi-on-command-state = "dsi_lp_mode";
				qcom,mdss-dsi-off-command =
					[05 01 00 00 32 00 02 28 00
					05 01 00 00 78 00 02 10 00];
				qcom,mdss-dsi-off-command-state = "dsi_hs_mode";
				qcom,mdss-dsi-qsync-on-commands =
					[15 01 00 00 00 00 02 51 00];
				qcom,mdss-dsi-qsync-on-commands-state =
					"dsi_hs_mode";
				qcom,mdss-dsi-qsync-off-commands =
					[15 01 00 00 00 00 02 51 00];
				qcom,mdss-dsi-qsync-off-commands-state =
					"dsi_hs_mode";

				qcom,compression-mode = "dsc";
				qcom,mdss-dsc-slice-height = <20>;
				qcom,mdss-dsc-slice-width = <720>;
				qcom,mdss-dsc-slice-per-pkt = <1>;
				qcom,mdss-dsc-bit-per-component = <8>;
				qcom,mdss-dsc-bit-per-pixel = <8>;
				qcom,mdss-dsc-block-prediction-enable;
			};

			timing_18_216: timing@18 {
				cell-index = <18>;
				qcom,mdss-dsi-panel-width = <1440>;
				qcom,mdss-dsi-panel-height = <3200>;
				qcom,mdss-dsi-h-front-porch = <20>;
				qcom,mdss-dsi-h-back-porch = <12>;
				qcom,mdss-dsi-h-pulse-width = <4>;
				qcom,mdss-dsi-h-sync-skew = <0>;
				qcom,mdss-dsi-v-back-porch = <20>;
				qcom,mdss-dsi-v-front-porch = <20>;
				qcom,mdss-dsi-v-pulse-width = <2>;
				qcom,mdss-dsi-panel-framerate = <180>;
				qcom,mdss-dsi-on-command =
					[29 01 00 00 00 00 02 b0 03
					05 01 00 00 0a 00 01 00
					/* Soft reset, wait 10ms */
					15 01 00 00 0a 00 02 3a 77
					/* Set Pixel format (24 bpp) */
					39 01 00 00 0a 00 05 2a 00 00 04 ff
					/* Set Column address */
					39 01 00 00 0a 00 05 2b 00 00 05 9f
					/* Set page address */
					15 01 00 00 0a 00 02 35 00
					/* Set tear on */
					39 01 00 00 0a 00 03 44 00 00
					/* Set tear scan line */
					15 01 00 00 0a 00 02 51 ff
					/* write display brightness */
					15 01 00 00 0a 00 02 53 24
					 /* write control brightness */
					15 01 00 00 0a 00 02 55 00
					/* CABC brightness */
					05 01 00 00 78 00 01 11
					/* exit sleep mode, wait 120ms */
					05 01 00 00 10 00 01 29];
					/* Set display on, wait 16ms */
				qcom,mdss-dsi-on-command-state = "dsi_lp_mode";
				qcom,mdss-dsi-off-command =
					[05 01 00 00 32 00 02 28 00
					05 01 00 00 78 00 02 10 00];
				qcom,mdss-dsi-off-command-state = "dsi_hs_mode";
				qcom,mdss-dsi-qsync-on-commands =
					[15 01 00 00 00 00 02 51 00];
				qcom,mdss-dsi-qsync-on-commands-state =
					"dsi_hs_mode";
				qcom,mdss-dsi-qsync-off-commands =
					[15 01 00 00 00 00 02 51 00];
				qcom,mdss-dsi-qsync-off-commands-state =
					"dsi_hs_mode";

				qcom,compression-mode = "dsc";
				qcom,mdss-dsc-slice-height = <20>;
				qcom,mdss-dsc-slice-width = <720>;
				qcom,mdss-dsc-slice-per-pkt = <1>;
				qcom,mdss-dsc-bit-per-component = <8>;
				qcom,mdss-dsc-bit-per-pixel = <8>;
				qcom,mdss-dsc-block-prediction-enable;
			};

			timing_19_217: timing@19 {
				cell-index = <19>;
				qcom,mdss-dsi-panel-width = <1440>;
				qcom,mdss-dsi-panel-height = <3200>;
				qcom,mdss-dsi-h-front-porch = <20>;
				qcom,mdss-dsi-h-back-porch = <12>;
				qcom,mdss-dsi-h-pulse-width = <4>;
				qcom,mdss-dsi-h-sync-skew = <0>;
				qcom,mdss-dsi-v-back-porch = <20>;
				qcom,mdss-dsi-v-front-porch = <20>;
				qcom,mdss-dsi-v-pulse-width = <2>;
				qcom,mdss-dsi-panel-framerate = <165>;
				qcom,mdss-dsi-on-command =
					[29 01 00 00 00 00 02 b0 03
					05 01 00 00 0a 00 01 00
					/* Soft reset, wait 10ms */
					15 01 00 00 0a 00 02 3a 77
					/* Set Pixel format (24 bpp) */
					39 01 00 00 0a 00 05 2a 00 00 04 ff
					/* Set Column address */
					39 01 00 00 0a 00 05 2b 00 00 05 9f
					/* Set page address */
					15 01 00 00 0a 00 02 35 00
					/* Set tear on */
					39 01 00 00 0a 00 03 44 00 00
					/* Set tear scan line */
					15 01 00 00 0a 00 02 51 ff
					/* write display brightness */
					15 01 00 00 0a 00 02 53 24
					 /* write control brightness */
					15 01 00 00 0a 00 02 55 00
					/* CABC brightness */
					05 01 00 00 78 00 01 11
					/* exit sleep mode, wait 120ms */
					05 01 00 00 10 00 01 29];
					/* Set display on, wait 16ms */
				qcom,mdss-dsi-on-command-state = "dsi_lp_mode";
				qcom,mdss-dsi-off-command =
					[05 01 00 00 32 00 02 28 00
					05 01 00 00 78 00 02 10 00];
				qcom,mdss-dsi-off-command-state = "dsi_hs_mode";
				qcom,mdss-dsi-qsync-on-commands =
					[15 01 00 00 00 00 02 51 00];
				qcom,mdss-dsi-qsync-on-commands-state =
					"dsi_hs_mode";
				qcom,mdss-dsi-qsync-off-commands =
					[15 01 00 00 00 00 02 51 00];
				qcom,mdss-dsi-qsync-off-commands-state =
					"dsi_hs_mode";

				qcom,compression-mode = "dsc";
				qcom,mdss-dsc-slice-height = <20>;
				qcom,mdss-dsc-slice-width = <720>;
				qcom,mdss-dsc-slice-per-pkt = <1>;
				qcom,mdss-dsc-bit-per-component = <8>;
				qcom,mdss-dsc-bit-per-pixel = <8>;
				qcom,mdss-dsc-block-prediction-enable;
			};

			timing_20_299: timing@20 {
				cell-index = <20>;
				qcom,mdss-dsi-panel-width = <1440>;
				qcom,mdss-dsi-panel-height = <3660>;
				qcom,mdss-dsi-h-front-porch = <20>;
				qcom,mdss-dsi-h-back-porch = <12>;
				qcom,mdss-dsi-h-pulse-width = <4>;
				qcom,mdss-dsi-h-sync-skew = <0>;
				qcom,mdss-dsi-v-back-porch = <20>;
				qcom,mdss-dsi-v-front-porch = <20>;
				qcom,mdss-dsi-v-pulse-width = <2>;
				qcom,mdss-dsi-panel-framerate = <180>;
				qcom,mdss-dsi-on-command =
					[29 01 00 00 00 00 02 b0 03
					05 01 00 00 0a 00 01 00
					/* Soft reset, wait 10ms */
					15 01 00 00 0a 00 02 3a 77
					/* Set Pixel format (24 bpp) */
					39 01 00 00 0a 00 05 2a 00 00 04 ff
					/* Set Column address */
					39 01 00 00 0a 00 05 2b 00 00 05 9f
					/* Set page address */
					15 01 00 00 0a 00 02 35 00
					/* Set tear on */
					39 01 00 00 0a 00 03 44 00 00
					/* Set tear scan line */
					15 01 00 00 0a 00 02 51 ff
					/* write display brightness */
					15 01 00 00 0a 00 02 53 24
					 /* write control brightness */
					15 01 00 00 0a 00 02 55 00
					/* CABC brightness */
					05 01 00 00 78 00 01 11
					/* exit sleep mode, wait 120ms */
					05 01 00 00 10 00 01 29];
					/* Set display on, wait 16ms */
				qcom,mdss-dsi-on-command-state = "dsi_lp_mode";
				qcom,mdss-dsi-off-command =
					[05 01 00 00 32 00 02 28 00
					05 01 00 00 78 00 02 10 00];
				qcom,mdss-dsi-off-command-state = "dsi_hs_mode";
				qcom,mdss-dsi-qsync-on-commands =
					[15 01 00 00 00 00 02 51 00];
				qcom,mdss-dsi-qsync-on-commands-state =
					"dsi_hs_mode";
				qcom,mdss-dsi-qsync-off-commands =
					[15 01 00 00 00 00 02 51 00];
				qcom,mdss-dsi-qsync-off-commands-state =
					"dsi_hs_mode";

				qcom,compression-mode = "dsc";
				qcom,mdss-dsc-slice-height = <20>;
				qcom,mdss-dsc-slice-width = <720>;
				qcom,mdss-dsc-slice-per-pkt = <1>;
				qcom,mdss-dsc-bit-per-component = <8>;
				qcom,mdss-dsc-bit-per-pixel = <8>;
				qcom,mdss-dsc-block-prediction-enable;
			};
		};
	};
};
